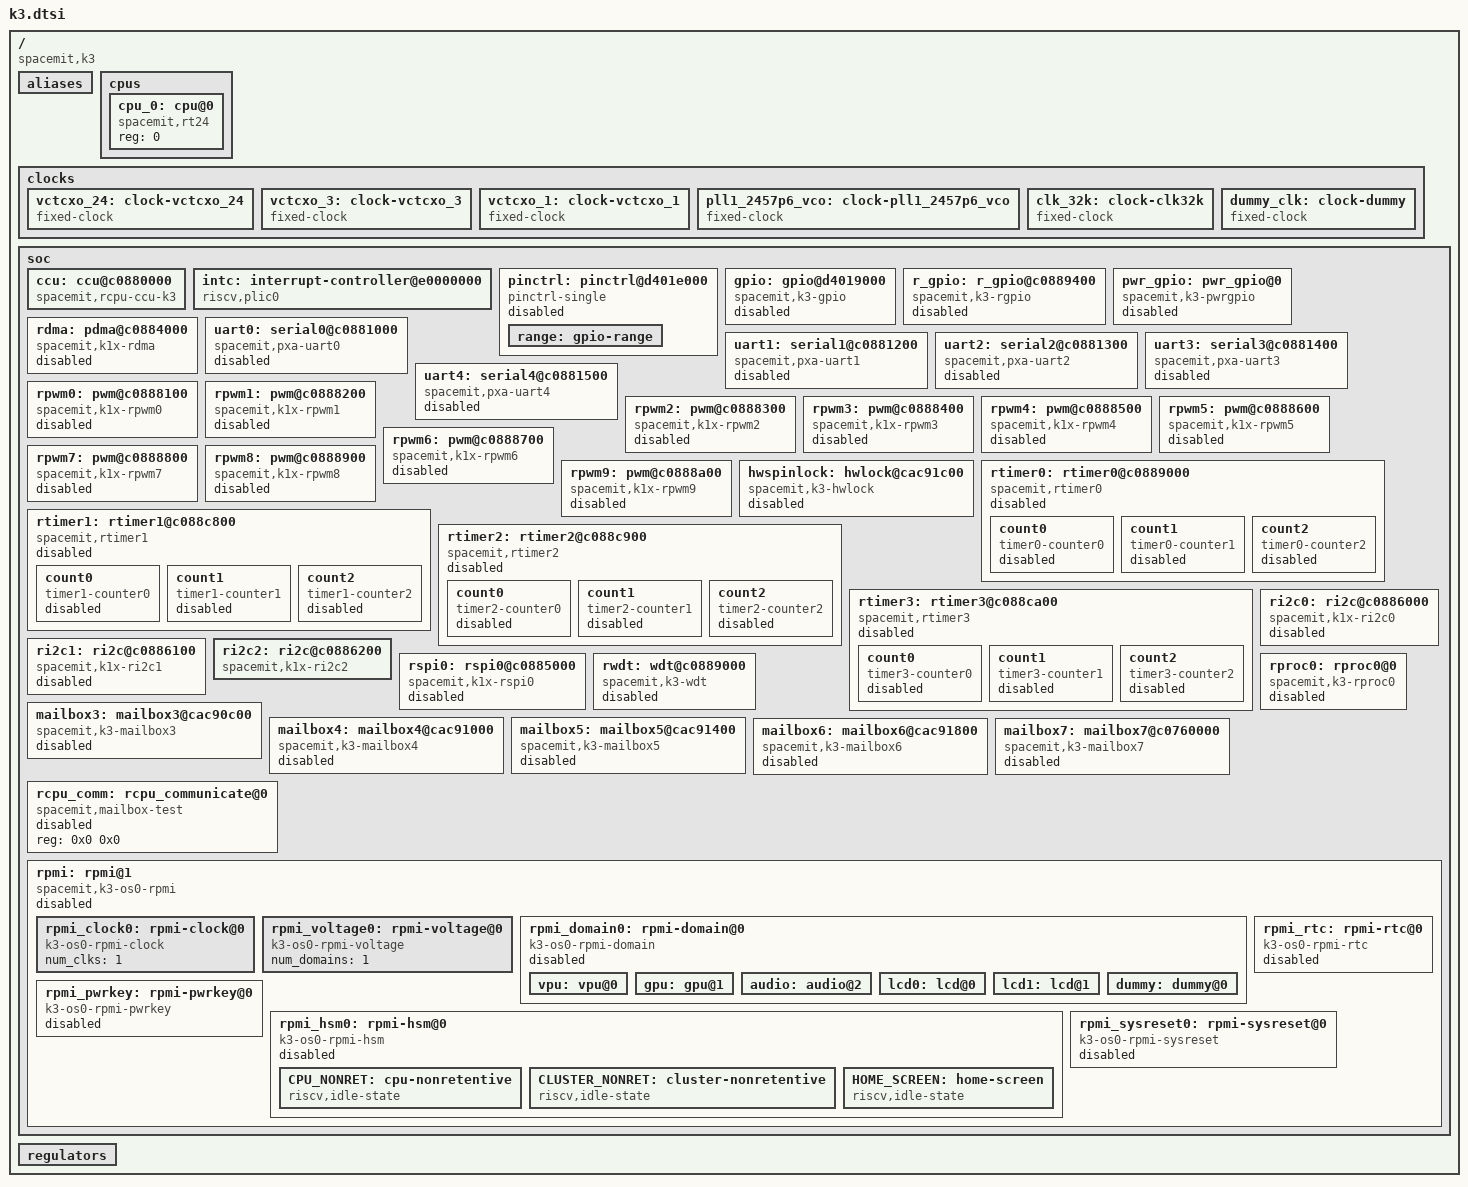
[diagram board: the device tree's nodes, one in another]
/*
 * Copyright (c) 2022-2025, Spacemit
 *
 * SPDX-License-Identifier: Apache-2.0
 */

/dts-v1/;

#include "../../ccu-spacemit-k3.h"

/ {
	compatible = "spacemit,k3";
	#address-cells = <2>;
	#size-cells = <2>;

	aliases: aliases {
	};

	cpus: cpus {
		#address-cells = <1>;
		#size-cells = <0>;

		cpu_0: cpu@0 {
			compatible = "spacemit,rt24", "riscv";
			device_type = "cpu";
			reg = <0>;
			status = "okay";
		};
	};

	clocks {
		#address-cells = <0x2>;
		#size-cells = <0x2>;
		ranges;

		vctcxo_24: clock-vctcxo_24 {
			#clock-cells = <0>;
			compatible = "fixed-clock";
			clock-frequency = <24000000>;
			clock-output-names = "vctcxo_24";
		};

		vctcxo_3: clock-vctcxo_3 {
			#clock-cells = <0>;
			compatible = "fixed-clock";
			clock-frequency = <3000000>;
			clock-output-names = "vctcxo_3";
		};

		vctcxo_1: clock-vctcxo_1 {
			#clock-cells = <0>;
			compatible = "fixed-clock";
			clock-frequency = <1000000>;
			clock-output-names = "vctcxo_1";
		};

		pll1_2457p6_vco: clock-pll1_2457p6_vco {
			#clock-cells = <0>;
			compatible = "fixed-clock";
			clock-frequency = <2457600000>;
			clock-output-names = "pll1_2457p6_vco";
		};

		clk_32k: clock-clk32k {
			#clock-cells = <0>;
			compatible = "fixed-clock";
			clock-frequency = <32000>;
			clock-output-names = "clk_32k";
		};

		dummy_clk: clock-dummy {
			#clock-cells = <0>;
			compatible = "fixed-clock";
			clock-frequency = <0>;
			clock-output-names = "dummy_clk";
		};
	};

	soc: soc {
		#address-cells = <1>;
		#size-cells = <1>;

		ccu: ccu@c0880000 {
			compatible = "spacemit,rcpu-ccu-k3";
			reg = <0xd4050000 0x209c>,
				<0xd4282800 0x400>,
				<0xd4090000 0x1000>,
				<0xc0880000 0x1000>,
				<0xc0881f00 0x100>,
				<0xc0882000 0x1000>,
				<0xc0885f00 0x100>,
				<0xc0886f00 0x100>,
				<0xc088c000 0x800>,
				<0xc088d000 0x100>;
			#clock-cells = <1>;
			status = "okay";
		};

		intc: interrupt-controller@e0000000 {
			#interrupt-cells = <3>;
			compatible = "riscv,plic0";
			interrupt-controller;
			reg = <0xe0000000 0x04000000>;
			status = "okay";
		};

		pinctrl: pinctrl@d401e000 {
			compatible = "pinctrl-single";
			reg = <0xd401e000 0x250>;
			#gpio-range-cells = <3>;
			pinctrl-single,bit-per-mux;
			pinctrl-single,register-width = <32>;
			pinctrl-single,function-mask = <0xff77>;
			status = "disabled";

			range: gpio-range {
				#pinctrl-single,gpio-range-cells = <3>;
			};
		};

		gpio: gpio@d4019000 {
			compatible = "spacemit,k3-gpio";
			reg = <0xd4019000 0x800>;
			banks = <4>;
			interrupt-parent = <&intc>;
			interrupts = <0 93 0>;
			gpio-controller;
			#gpio-cells = <2>;
			status = "disabled";
		};

		r_gpio: r_gpio@c0889400 {
			compatible = "spacemit,k3-rgpio";
			reg = <0xc0889400 0x100>;
			clocks = <&ccu CLK_RCPU_GPIO>, <&ccu CLK_RST_RCPU_GPIO>;
			banks = <2>;
			interrupt-parent = <&intc>;
			interrupts = <0 49 0>;
			gpio-controller;
			#gpio-cells = <2>;
			status = "disabled";
		};

		pwr_gpio: pwr_gpio@0 {
			compatible = "spacemit,k3-pwrgpio";
			reg = <0x0 0x0>;
			bind_driver = "ri2c2";
			slave_addr = <0x41>;
			gpio_base = <0>;
			ngpios = <6>;
			gpio-controller;
			#gpio-cells = <2>;
			status = "disabled";
		};

		rdma: pdma@c0884000 {
			compatible = "spacemit,k1x-rdma";
			reg = <0xc0884000 0x470>;
			interrupt-parent = <&intc>;
			interrupts = <0 32 0>;
			#dma-cells= <2>;
			#dma-channels = <16>;
			max-burst-size = <64>;
			status = "disabled";
		};

		uart0: serial0@c0881000 {
			compatible = "spacemit,pxa-uart0";
			// reg = <0xc0881000 0x100>;
			/* the uart of RCPU on fpga is multiplexed with AP */
			reg = <0xd4017000 0x100>;
			interrupt-parent = <&intc>;
			interrupts = <0 17 0>;
			clocks = <&ccu CLK_RCPU_UART0>, <&ccu CLK_RST_RCPU_UART0>;
			status = "disabled";
		};

		uart1: serial1@c0881200 {
			compatible = "spacemit,pxa-uart1";
			reg = <0xc0881200 0x100>;
			interrupt-parent = <&intc>;
			interrupts = <0 19 0>;
			clocks = <&ccu CLK_RCPU_UART2>, <&ccu CLK_RST_RCPU_UART2>;
			status = "disabled";
		};

		uart2: serial2@c0881300 {
			compatible = "spacemit,pxa-uart2";
			reg = <0xc0881300 0x100>;
			interrupt-parent = <&intc>;
			interrupts = <0 20 0>;
			clocks = <&ccu CLK_RCPU_UART3>, <&ccu CLK_RST_RCPU_UART3>;
			status = "disabled";
		};

		uart3: serial3@c0881400 {
			compatible = "spacemit,pxa-uart3";
			reg = <0xc0881400 0x100>;
			interrupt-parent = <&intc>;
			interrupts = <0 21 0>;
			clocks = <&ccu CLK_RCPU_UART4>, <&ccu CLK_RST_RCPU_UART4>;
			status = "disabled";
		};

		uart4: serial4@c0881500 {
			compatible = "spacemit,pxa-uart4";
			reg = <0xc0881500 0x100>;
			interrupt-parent = <&intc>;
			interrupts = <0 44 0>;
			clocks = <&ccu CLK_RCPU_UART5>, <&ccu CLK_RST_RCPU_UART5>;
			status = "disabled";
		};

		rpwm0: pwm@c0888100 {
			compatible = "spacemit,k1x-rpwm0";
			reg = <0xc0888100 0x10>;
			clocks = <&ccu CLK_RCPU_PWM0>, <&ccu CLK_RST_RCPU_PWM0>;
			clock-rate = <24576000>;
			k1x,pwm-disable-fd;
			status = "disabled";
		};

		rpwm1: pwm@c0888200 {
			compatible = "spacemit,k1x-rpwm1";
			reg = <0xc0888200 0x10>;
			clocks = <&ccu CLK_RCPU_PWM1>, <&ccu CLK_RST_RCPU_PWM1>;
			clock-rate = <24576000>;
			k1x,pwm-disable-fd;
			status = "disabled";
		};

		rpwm2: pwm@c0888300 {
			compatible = "spacemit,k1x-rpwm2";
			reg = <0xc0888300 0x10>;
			clocks = <&ccu CLK_RCPU_PWM2>, <&ccu CLK_RST_RCPU_PWM2>;
			clock-rate = <24576000>;
			k1x,pwm-disable-fd;
			status = "disabled";
		};

		rpwm3: pwm@c0888400 {
			compatible = "spacemit,k1x-rpwm3";
			reg = <0xc0888400 0x10>;
			clocks = <&ccu CLK_RCPU_PWM3>, <&ccu CLK_RST_RCPU_PWM3>;
			clock-rate = <24576000>;
			k1x,pwm-disable-fd;
			status = "disabled";
		};

		rpwm4: pwm@c0888500 {
			compatible = "spacemit,k1x-rpwm4";
			reg = <0xc0888500 0x10>;
			clocks = <&ccu CLK_RCPU_PWM4>, <&ccu CLK_RST_RCPU_PWM4>;
			clock-rate = <24576000>;
			k1x,pwm-disable-fd;
			status = "disabled";
		};

		rpwm5: pwm@c0888600 {
			compatible = "spacemit,k1x-rpwm5";
			reg = <0xc0888600 0x10>;
			clocks = <&ccu CLK_RCPU_PWM5>, <&ccu CLK_RST_RCPU_PWM5>;
			clock-rate = <24576000>;
			k1x,pwm-disable-fd;
			status = "disabled";
		};

		rpwm6: pwm@c0888700 {
			compatible = "spacemit,k1x-rpwm6";
			reg = <0xc0888700 0x10>;
			clocks = <&ccu CLK_RCPU_PWM6>, <&ccu CLK_RST_RCPU_PWM6>;
			clock-rate = <24576000>;
			k1x,pwm-disable-fd;
			status = "disabled";
		};

		rpwm7: pwm@c0888800 {
			compatible = "spacemit,k1x-rpwm7";
			reg = <0xc0888800 0x10>;
			clocks = <&ccu CLK_RCPU_PWM7>, <&ccu CLK_RST_RCPU_PWM7>;
			clock-rate = <24576000>;
			k1x,pwm-disable-fd;
			status = "disabled";
		};

		rpwm8: pwm@c0888900 {
			compatible = "spacemit,k1x-rpwm8";
			reg = <0xc0888900 0x10>;
			clocks = <&ccu CLK_RCPU_PWM8>, <&ccu CLK_RST_RCPU_PWM8>;
			clock-rate = <24576000>;
			k1x,pwm-disable-fd;
			status = "disabled";
		};

		rpwm9: pwm@c0888a00 {
			compatible = "spacemit,k1x-rpwm9";
			reg = <0xc0888a00 0x10>;
			clocks = <&ccu CLK_RCPU_PWM9>, <&ccu CLK_RST_RCPU_PWM9>;
			clock-rate = <24576000>;
			k1x,pwm-disable-fd;
			status = "disabled";
		};

		hwspinlock: hwlock@cac91c00 {
			compatible = "spacemit,k3-hwlock";
			reg = <0xcac91c00 0x100>;
			num_locks = <32>;
			status = "disabled";
		};

		rtimer0: rtimer0@c0889000 {
			compatible = "spacemit,rtimer0";
			reg = <0xc0889000 0xc8>;
			num_counter = <3>;
			spacemit,timer-fastclk-frequency = <3250000>;
			spacemit,timer-apb-frequency = <52000000>;
			spacemit,timer-frequency = <1000000>;
			clocks = <&ccu CLK_RCPU_TIMER1>, <&ccu CLK_RST_RCPU_TIMER1>;
			status = "disabled";

			count0 {
				compatible = "timer0-counter0";
				interrupt-parent = <&intc>;
				interrupts = <0 8 0>;
				status = "disabled";
			};

			count1 {
				compatible = "timer0-counter1";
				interrupt-parent = <&intc>;
				interrupts = <0 9 0>;
				status = "disabled";
			};

			count2 {
				compatible = "timer0-counter2";
				interrupt-parent = <&intc>;
				interrupts = <0 10 0>;
				status = "disabled";
			};
		};

		rtimer1: rtimer1@c088c800 {
			compatible = "spacemit,rtimer1";
			reg = <0xc088c800 0xc8>;
			num_counter = <3>;
			spacemit,timer-fastclk-frequency = <3250000>;
			spacemit,timer-apb-frequency = <52000000>;
			spacemit,timer-frequency = <1000000>;
			clocks = <&ccu CLK_RCPU_TIMER2>, <&ccu CLK_RST_RCPU_TIMER2>;
			status = "disabled";

			count0 {
				compatible = "timer1-counter0";
				interrupt-parent = <&intc>;
				interrupts = <0 46 0>;
				status = "disabled";
			};

			count1 {
				compatible = "timer1-counter1";
				interrupt-parent = <&intc>;
				interrupts = <0 47 0>;
				status = "disabled";
			};

			count2 {
				compatible = "timer1-counter2";
				interrupt-parent = <&intc>;
				interrupts = <0 48 0>;
				status = "disabled";
			};
		};

		rtimer2: rtimer2@c088c900 {
			compatible = "spacemit,rtimer2";
			reg = <0xc088c900 0xc8>;
			num_counter = <3>;
			spacemit,timer-fastclk-frequency = <3250000>;
			spacemit,timer-apb-frequency = <52000000>;
			spacemit,timer-frequency = <1000000>;
			clocks = <&ccu CLK_RCPU_TIMER3>, <&ccu CLK_RST_RCPU_TIMER3>;
			status = "disabled";

			count0 {
				compatible = "timer2-counter0";
				interrupt-parent = <&intc>;
				interrupts = <0 76 0>;
				status = "disabled";
			};

			count1 {
				compatible = "timer2-counter1";
				interrupt-parent = <&intc>;
				interrupts = <0 77 0>;
				status = "disabled";
			};

			count2 {
				compatible = "timer2-counter2";
				interrupt-parent = <&intc>;
				interrupts = <0 78 0>;
				status = "disabled";
			};
		};

		rtimer3: rtimer3@c088ca00 {
			compatible = "spacemit,rtimer3";
			reg = <0xc088ca00 0xc8>;
			num_counter = <3>;
			spacemit,timer-fastclk-frequency = <3250000>;
			spacemit,timer-apb-frequency = <52000000>;
			spacemit,timer-frequency = <1000000>;
			clocks = <&ccu CLK_RCPU_TIMER4>, <&ccu CLK_RST_RCPU_TIMER4>;
			status = "disabled";

			count0 {
				compatible = "timer3-counter0";
				interrupt-parent = <&intc>;
				interrupts = <0 79 0>;
				status = "disabled";
			};

			count1 {
				compatible = "timer3-counter1";
				interrupt-parent = <&intc>;
				interrupts = <0 80 0>;
				status = "disabled";
			};

			count2 {
				compatible = "timer3-counter2";
				interrupt-parent = <&intc>;
				interrupts = <0 81 0>;
				status = "disabled";
			};
		};

		ri2c0: ri2c@c0886000 {
			compatible = "spacemit,k1x-ri2c0";
			reg = <0xc0886000 0x38>;
			/* usually i2c client has only 1 reg field */
			clocks = <&ccu CLK_RCPU_I2C0>, <&ccu CLK_RST_RCPU_I2C0>;
			interrupt-parent = <&intc>;
			interrupts = <0 13 0>;
			/* spacemit,i2c-fast-mode; */
			/* spacemit,i2c-high-mode; */
			spacemit,i2c-master-code = /bits/ 8 <0x0e>;
			spacemit,i2c-clk-rate = <32000000>;
			spacemit,i2c-lcr = <0x82c469f>;
			spacemit,i2c-wcr = <0x142a>;
			status = "disabled";
		};

		ri2c1: ri2c@c0886100 {
			compatible = "spacemit,k1x-ri2c1";
			reg = <0xc0886100 0x38>;
			/* usually i2c client has only 1 reg field */
			clocks = <&ccu CLK_RCPU_I2C1>, <&ccu CLK_RST_RCPU_I2C1>;
			interrupt-parent = <&intc>;
			interrupts = <0 14 0>;
			/* spacemit,i2c-fast-mode; */
			/* spacemit,i2c-high-mode; */
			spacemit,i2c-master-code = /bits/ 8 <0x0e>;
			spacemit,i2c-clk-rate = <32000000>;
			spacemit,i2c-lcr = <0x82c469f>;
			spacemit,i2c-wcr = <0x142a>;
			status = "disabled";
		};

		ri2c2: ri2c@c0886200 {
			compatible = "spacemit,k1x-ri2c2";
			reg = <0xc0886200 0x38>;
			/* usually i2c client has only 1 reg field */
			clocks = <&ccu CLK_RCPU_I2C2>, <&ccu CLK_RST_RCPU_I2C2>;
			interrupt-parent = <&intc>;
			interrupts = <0 82 0>;
			/* spacemit,i2c-fast-mode; */
			/* spacemit,i2c-high-mode; */
			spacemit,i2c-master-code = /bits/ 8 <0x0e>;
			spacemit,i2c-clk-rate = <32000000>;
			spacemit,i2c-lcr = <0x82c469f>;
			spacemit,i2c-wcr = <0x142a>;
			status = "okay";
		};

		rspi0: rspi0@c0885000 {
			compatible = "spacemit,k1x-rspi0";
			reg = <0xc0885000 0x30>;
			clocks = <&ccu CLK_RCPU_SPI0>, <&ccu CLK_RST_RCPU_SPI0>;
			clock-frequency = <26000000>;
			interrupt-parent = <&intc>;
			interrupts = <0 15 0>;
			dmas = <&rdma 5 1
				&rdma 4 1>;
			dma-names = "rx", "tx";
			/* k1x,ssp-disable-dma; */
			status = "disabled";
		};

		rwdt: wdt@c0889000 {
			compatible = "spacemit,k3-wdt";
			reg = <0xc0889000 0x100>,
			      <0xd4050000 0x1030>;
			clocks = <&ccu CLK_RCPU_TIMER1>, <&ccu CLK_RST_RCPU_TIMER1>;
			status = "disabled";
		};

		mailbox3: mailbox3@cac90c00 {
			compatible = "spacemit,k3-mailbox3";
			reg = <0xcac90c00 0x400>;
			/* put here to register the mailbox irq */
			interrupt-parent = <&intc>;
			interrupts = <0 68 0>;
			#mbox-cells = <1>;
			status = "disabled";
		};

		mailbox4: mailbox4@cac91000 {
			compatible = "spacemit,k3-mailbox4";
			reg = <0xcac91000 0x400>;
			/* put here to register the mailbox irq */
			interrupt-parent = <&intc>;
			interrupts = <0 69 0>;
			#mbox-cells = <1>;
			status = "disabled";
		};

		mailbox5: mailbox5@cac91400 {
			compatible = "spacemit,k3-mailbox5";
			reg = <0xcac91400 0x400>;
			/* put here to register the mailbox irq */
			interrupt-parent = <&intc>;
			interrupts = <0 70 0>;
			#mbox-cells = <1>;
			status = "disabled";
		};

		mailbox6: mailbox6@cac91800 {
			compatible = "spacemit,k3-mailbox6";
			reg = <0xcac91800 0x400>;
			/* put here to register the mailbox irq */
			interrupt-parent = <&intc>;
			interrupts = <0 71 0>;
			#mbox-cells = <1>;
			status = "disabled";
		};

		mailbox7: mailbox7@c0760000 {
			compatible = "spacemit,k3-mailbox7";
			reg = <0xc0760000 0x400>;
			/* put here to register the mailbox irq */
			interrupt-parent = <&intc>;
			interrupts = <0 65 0>;
			#mbox-cells = <1>;
			status = "disabled";
		};

		rcpu_comm: rcpu_communicate@0 {
			compatible = "spacemit,mailbox-test";
			reg = <0x0 0x0>;
			status = "disabled";
		};

		rproc0: rproc0@0 {
			compatible = "spacemit,k3-rproc0";
			reg = <0x0 0x0>;
			shared_mem_pa_base = <0x0 0xc0876000>;
			shared_mem_buf_offset = <0x3fe8a000>;
			shared_mem_size	= <0x3ff86000>;
			proc_id = <0>;
			rsc_id = <0>;
			vdev_id = <0>;
			mbox-names = "vq0", "vq1";
			status = "disabled";
		};

		/* RPMI node, similar structure to rproc for mailbox communication */
		rpmi: rpmi@1 {
			compatible = "spacemit,k3-os0-rpmi";
			#address-cells = <1>;
			#size-cells = <1>;
			reg = <0x0 0x0>;
			status = "disabled";
			mbox-names = "rpmi_mbox";

			/* Shared memory configuration */
			shmem-base = <0x1 0x800000>;
			shmem-size = <0x4000>;

			/* Message and queue configuration */
			slot-size = <256>;
			a2p-queue-size = <4096>;
			p2a-queue-size = <4096>;

			rpmi_clock0: rpmi-clock@0 {
				compatible = "k3-os0-rpmi-clock";
				num_clks = <1>;
				status = "okay";
			};

			rpmi_voltage0: rpmi-voltage@0 {
				compatible = "k3-os0-rpmi-voltage";
				num_domains = <1>;
				status = "okay";
			};

			rpmi_domain0: rpmi-domain@0 {
				compatible = "k3-os0-rpmi-domain";
				status = "disabled";
				num_domains = <6>;
				reg = <0xd4282800 0x400>;

				vpu: vpu@0 {
					bit_isolation = <1>;
					bit_sleep1 = <2>;
					bit_sleep2 = <3>;
					bit_pwr_stat = <1>;
					offset = <0xa8>;
				};

				gpu: gpu@1 {
					bit_isolation = <1>;
					bit_sleep1 = <2>;
					bit_sleep2 = <3>;
					bit_pwr_stat = <0>;
					offset = <0xd0>;
				};

				audio: audio@2 {
					bit_isolation = <1>;
					bit_sleep1 = <2>;
					bit_sleep2 = <3>;
					bit_hw_mode = <4>;
					bit_pwr_stat = <3>;
					/* bit_auto_pwr_on = <1>; */
					offset = <0x378>;
				};

				lcd0: lcd@0 {
					bit_isolation = <1>;
					bit_sleep1 = <2>;
					bit_sleep2 = <3>;
					bit_hw_mode = <4>;
					bit_pwr_stat = <4>;
					/* bit_auto_pwr_on = <1>; */
					offset = <0x380>;
				};

				lcd1: lcd@1 {
					bit_isolation = <1>;
					bit_sleep1 = <2>;
					bit_sleep2 = <3>;
					bit_hw_mode = <4>;
					bit_pwr_stat = <5>;
					/* bit_auto_pwr_on = <1>; */
					offset = <0x3f4>;
				};

				dummy: dummy@0 {
				};
			};

			rpmi_rtc: rpmi-rtc@0 {
				compatible = "k3-os0-rpmi-rtc";
				status = "disabled";
			};

			rpmi_pwrkey: rpmi-pwrkey@0 {
				compatible = "k3-os0-rpmi-pwrkey";
				status = "disabled";
			};

			rpmi_hsm0: rpmi-hsm@0 {
				compatible = "k3-os0-rpmi-hsm";
				/* hartids*/
				hartids = <0x0 0x1 0x2 0x3 0x4 0x5 0x6 0x7 0x8 0x9 0xa 0xb 0xc 0xd 0xe 0xf>;

				risv,support-syssup = <1>;

				status = "disabled";

				CPU_NONRET: cpu-nonretentive {
					compatible = "riscv,idle-state";
					riscv,sbi-suspend-param = <0x90000000>;
					local-timer-stop;
					entry-latency-us = <250>;
					exit-latency-us = <500>;
					min-residency-us = <950>;
				};

				CLUSTER_NONRET: cluster-nonretentive {
					compatible = "riscv,idle-state";
					riscv,sbi-suspend-param = <0x91000000>;
					local-timer-stop;
					entry-latency-us = <600>;
					exit-latency-us = <1100>;
					min-residency-us = <2700>;
					wakeup-latency-us = <1500>;
				};

				HOME_SCREEN: home-screen {
					compatible = "riscv,idle-state";
					riscv,sbi-suspend-param = <0x92000000>;
					local-timer-stop;
					entry-latency-us = <600>;
					exit-latency-us = <1100>;
					min-residency-us = <2700>;
					wakeup-latency-us = <1500>;
				};
			};

			rpmi_sysreset0: rpmi-sysreset@0 {
				compatible = "k3-os0-rpmi-sysreset";
				status = "disabled";
			};
		};
	};

	regulators: regulators {
	};
};
